# H616 register map
Vendor: Allwinner; Series: H616; File version: 0.1
CPU: other 0, little endian, MPU, no FPU, 0 interrupt priority bits
Registers are 32-bit, read-write, reset 0x0 unless marked. A register's access mark holds for its fields unless they carry their own. Offsets are from the block's base; [hi:lo] are bit positions; {n}, {i} and the like mark numbered series; 'fields as' and 'values as' point back to an identical list.

## NDFC
Base 0x04011000
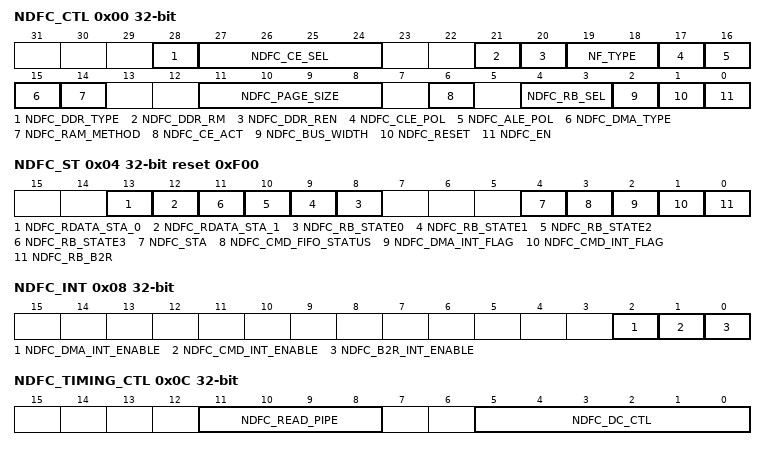
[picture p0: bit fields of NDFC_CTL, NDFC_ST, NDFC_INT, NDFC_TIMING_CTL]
0x00 NDFC_CTL — NDFC Configure and Control Register
  [28] NDFC_DDR_TYPE — Type of DDR data interface This bit is valid when NF_TYPE is 0x2 or 0x3. 0: DDR 1: DDR2
    0=DDR; 1=DDR2
  [27:24] NDFC_CE_SEL — Chip Select for NAND Flash Chips 0000: NDFC Select Chip 0 0001: NDFC Select Chip 1 0010: NDFC Select Chip 2 0011: NDFC Select Chip 3 0100: NDFC Select Chip 4 0101: NDFC Select Chip 5 0110: NDFC Select Chip 6 0111: NDFC Select Chip 7 1000: NDFC Select Chip 8 1001: NDFC Select Chip 9 1010: NDFC Select Chip 10 1011: NDFC Select Chip 11 1100: NDFC Select Chip 12 1101: NDFC Select Chip 13 1110: NDFC Select Chip 14 1111: NDFC Select Chip 15
    {v}=NDFC_Select_Chip_{v} (v=0..15)
  [21] NDFC_DDR_RM — DDR Repeat Data Mode 0: Lower byte 1: Higher byte
    0=Lower byte; 1=Higher byte
  [20] NDFC_DDR_REN — DDR Repeat Enable 0: Disable 1: Enable
    0=Disable; 1=Enable
  [19:18] NF_TYPE — NAND Flash Type 00: Normal SDR NAND 01: Reserved 10: ONFI DDR NAND 11: Toggle DDR NAND
    0=Normal SDR NAND; 2=ONFI (ONFI DDR NAND); 3=Toggle DDR NAND
  [17] NDFC_CLE_POL — NDFC Command Latch Enable (CLE) Signal Polarity Select 0: High active 1: Low active
    0=High active; 1=Low (Low active)
  [16] NDFC_ALE_POL — NDFC Address Latch Enable (ALE) Signal Polarity Select 0: High active 1: Low active
    0=High active; 1=Low (Low active)
  [15] NDFC_DMA_TYPE — 0: Dedicated DMA 1: Normal DMA
    0=Dedicated DMA; 1=Normal DMA
  [14] NDFC_RAM_METHOD — Access internal RAM method 0: Access internal RAM by AHB method 1: Access internal RAM by DMA method
    0=Access internal RAM by AHB method; 1=Access internal RAM by DMA method
  [11:8] NDFC_PAGE_SIZE — 000: 1KB 001: 2KB 010: 4KB 011: 8KB 100: 16KB 101: 32KB The page size is for main field data.
  [6] NDFC_CE_ACT — Chip Select Signal CE# Control during NAND Operation 0: De-active Chip Select Signal NDFC_CE# during data loading, serial access and other no operation stage for power consumption. NDFC automatic controls Chip Select Signals. 1: Chip select signal NDFC_CE# is always active after NDFC is enabled
    0=De-active Chip Select Signal NDFC_CE# during data loading, serial access and other no operation stage for power consumption. NDFC automatic controls Chip Select Signals.; 1=Chip select signal NDFC_CE# is always active after NDFC is enabled
  [4:3] NDFC_RB_SEL — NDFC External R/B Signal Select The value 0-3 selects the external R/B signal. The same R/B signal can be used for multiple chip select flash.
  [2] NDFC_BUS_WIDTH — 0: 8-bit bus 1: 16-bit bus
    0=8-bit bus; 1=16-bit bus
  [1] NDFC_RESET write-1-clears — NDFC Reset Write 1 to reset NDFC and clear to 0 after reset
  [0] NDFC_EN — NDFC Enable Control 0: Disable NDFC 1: Enable NDFC
    0=Disable NDFC; 1=Enable NDFC
0x04 NDFC_ST reset 0xF00 — NDFC Status Information Register
  [13] NDFC_RDATA_STA_0 ro — 0: The number of bit 1 during current read operation is more than threshold value. 1: The number of bit 1 during current read operation is less than or equal to threshold value. This field only is valid when NDFC_RDATA_STA_EN is 1. The threshold value is configured in NDFC_RDATA_STA_TH.
    0=more (The number of bit 1 during current read operation is more than threshold value.); 1=less (The number of bit 1 during current read operation is less than or equal to threshold value. This field only is valid when NDFC_RDATA_STA_EN is 1. The threshold value is configured in NDFC_RDATA_STA_TH.)
  [12] NDFC_RDATA_STA_1 ro — 0: The number of bit 0 during current read operation is more than threshold value. 1: The number of bit 0 during current read operation is less than or equal to the threshold value. This field only is valid when NDFC_RDATA_STA_EN is 1. The threshold value is configured in NDFC_RDATA_STA_TH.
    0=more (The number of bit 0 during current read operation is more than threshold value.); 1=less (The number of bit 0 during current read operation is less than or equal to the threshold value. This field only is valid when NDFC_RDATA_STA_EN is 1. The threshold value is configured in NDFC_RDATA_STA_TH.)
  [n+8] NDFC_RB_STATE{n} ro (n=0..3) — NAND Flash R/B {n} Line State 0: NAND Flash in BUSY State 1: NAND Flash in READY State
    0=NAND Flash in BUSY State; 1=NAND Flash in READY State
  [4] NDFC_STA ro — 0: NDFC FSM in IDLE state 1: NDFC FSM in BUSY state When NDFC_STA is 0, NDFC can accept new command and process command.
    0=NDFC FSM in IDLE state; 1=NDFC FSM in BUSY state When NDFC_STA is 0, NDFC can accept new command and process command
  [3] NDFC_CMD_FIFO_STATUS ro — 0: Command FIFO not full and can receive new command 1: Full and waiting NDFC to process commands in FIFO Since there is only one 32-bit FIFO for command. When NDFC latches one command, command FIFO is free and can accept another new command.
    0=Command FIFO not full and can receive new command; 1=Full and waiting NDFC to process commands in FIFO Since there is only one 32-bit FIFO for command. When NDFC latches one command, command FIFO is free and can accept another new command.
  [2] NDFC_DMA_INT_FLAG write-1-clears — When it is 1, it means that a pending DMA is completed. It will be cleared after writing 1 to this bit or it will be automatically cleared before FSM processing an new command.
  [1] NDFC_CMD_INT_FLAG write-1-clears — When it is 1, it means that NDFC has finished one Normal Command Mode or one Batch Command Work Mode. It will be cleared after writing 1 to this bit or it will be automatically cleared before FSM processing an new command.
  [0] NDFC_RB_B2R write-1-clears — When it is 1, it means that NDFC_R/B# signal is transferred from BUSY state to READY state. It will be cleared after writing 1 to this bit.
0x08 NDFC_INT — NDFC Interrupt Control Register
  [2] NDFC_DMA_INT_ENABLE — Enable or disable interrupt when a pending DMA is completed.
  [1] NDFC_CMD_INT_ENABLE — Enable or disable interrupt when NDFC has finished the procession of a single command in normal command work mode or one batch command work mode. 0: Disable 1: Enable
    0=Disable; 1=Enable
  [0] NDFC_B2R_INT_ENABLE — Enable or disable interrupt when NDFC_RB# signal is transferring from BUSY state to READY state. 0: Disable 1: Enable
    0=Disable; 1=Enable
0x0C NDFC_TIMING_CTL — NDFC Timing Control Register
  [11:8] NDFC_READ_PIPE — In SDR mode: 00: Normal 01: EDO 10: E-EDO Others: Reserved In DDR mode: 1~15 is valid.(These bits configure the number of clock when data is valid after RE#`s falling edge)
  [5:0] NDFC_DC_CTL — NDFC Delay Chain Control. These bits are only valid in DDR data interface, and configure the relative phase between DQS and DQ[0...7] .
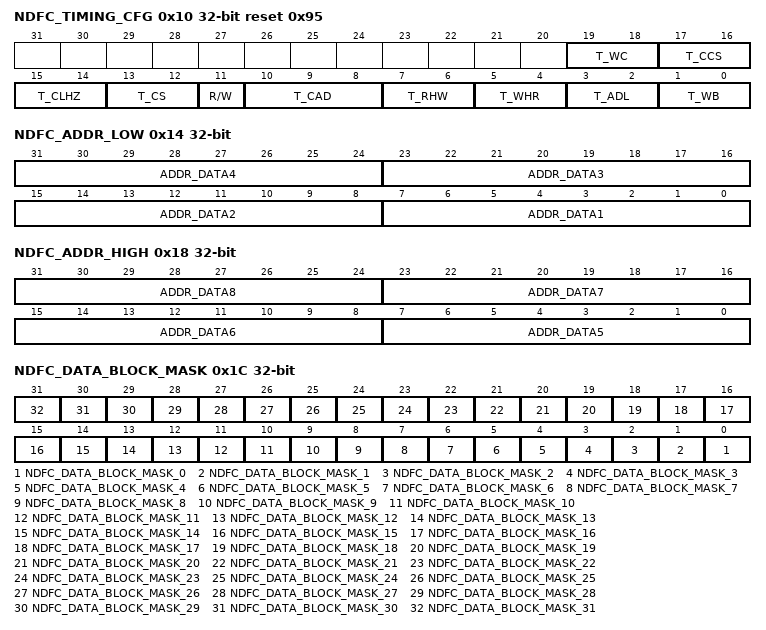
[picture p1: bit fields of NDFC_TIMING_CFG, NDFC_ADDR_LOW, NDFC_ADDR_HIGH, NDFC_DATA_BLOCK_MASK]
0x10 NDFC_TIMING_CFG reset 0x95 — NDFC Timing Configure Register
  [19:18] T_WC — Write Cycle Time 00: 1*2T 01: 2*2T 10: 3*2T 11: 4*2T
    {v}=_{v+1}_times_2T ({v+1}*2T) (v=0..3)
  [17:16] T_CCS — Change Column Setup Time 00: 12*2T 01: 20*2T 10: 28*2T 11: 60*2T
    0=_12_times_2T (12*2T); 1=_20_times_2T (20*2T); 2=_28_times_2T (28*2T); 3=_60_times_2T (60*2T)
  [15:14] T_CLHZ — CLE High to Output Hi-z 00: 2*2T 01: 8*2T 10: 16*2T 11: 31*2T
    0=_2_times_2T (2*2T); 1=_8_times_2T (8*2T); 2=_16_times_2T (16*2T); 3=_31_times_2T (31*2T)
  [13:12] T_CS — CE Setup Time 00: 2*2T 01: 8*2T 10: 16*2T 11: 31*2T
    values as T_CLHZ
  [11] R/W — 0x0 T_CDQSS DQS Setup Time for Data Input Start 0: 4*2T 1: 20*2T
    0=_4_times_2T (4*2T); 1=_20_times_2T (20*2T)
  [10:8] T_CAD — Command, Address, Data Delay 000: 2*2T 001: 6*2T 010: 10*2T 011: 14*2T 100: 22*2T 101: 30*2T 110/111: 62*2T
    0=_2_times_2T (2*2T); 1=_6_times_2T (6*2T); 2=_10_times_2T (10*2T); 3=_14_times_2T (14*2T); 4=_22_times_2T (22*2T); 5=_30_times_2T (30*2T 110/111: 62*2T)
  [7:6] T_RHW — Cycle Number from RE# High to WE# Low 00: 4*2T 01: 12*2T 10: 20*2T 11: 28*2T
    0=_4_times_2T (4*2T); 1=_12_times_2T (12*2T); 2=_20_times_2T (20*2T); 3=_28_times_2T (28*2T)
  [5:4] T_WHR — Cycle Number from WE# High to RE# Low 00: 0*2T 01: 6*2T 10: 14*2T 11: 22*2T
    0=_0_times_2T (0*2T); 1=_6_times_2T (6*2T); 2=_14_times_2T (14*2T); 3=_22_times_2T (22*2T)
  [3:2] T_ADL — Cycle Number from Address to Data Loading 00: 0*2T 01: 6*2T 10: 14*2T 11: 22*2T
    values as T_WHR
  [1:0] T_WB — Cycle Number from WE# High to Busy 00:14*2T 01: 22*2T 10: 30*2T 11: 38*2T
    1=_22_times_2T (22*2T); 2=_30_times_2T (30*2T); 3=_38_times_2T (38*2T)
0x14 NDFC_ADDR_LOW — NDFC Low Word Address Register
  [31:24] ADDR_DATA4 — NAND Flash 4th Cycle Address Data
  [23:16] ADDR_DATA3 — NAND Flash 3rd Cycle Address Data
  [15:8] ADDR_DATA2 — NAND Flash 2nd Cycle Address Data
  [7:0] ADDR_DATA1 — NAND Flash 1st Cycle Address Data
0x18 NDFC_ADDR_HIGH — NDFC High Word Address Register
  [8n-33:8n-40] ADDR_DATA{n} (n=5..8) — NAND Flash {n}th Cycle Address Data
0x1C NDFC_DATA_BLOCK_MASK
  [all] fields
    0=Disable; 1=Enable 1 data block = 1024 bytes main field data
  [n] NDFC_DATA_BLOCK_MASK_{n} (n=0..31) — It is used to indicate the data block {n} should be written or read during batch command procession(NDFC_CMD_TYPE=0x10 in NDFC_CMD ). 0: Disable 1: Enable 1 data block = 1024 bytes main field data.
0x20 NDFC_CNT — NDFC Data Counter Register
  [9:0] NDFC_DATA_CNT — Transfer Data Byte Counter The length can be set from 1 byte to 1024 bytes. However, 1024 bytes is set when it is zero.
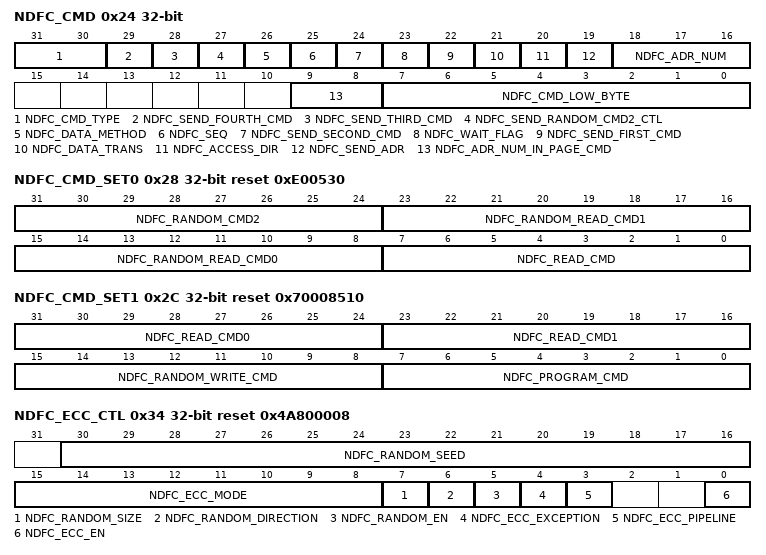
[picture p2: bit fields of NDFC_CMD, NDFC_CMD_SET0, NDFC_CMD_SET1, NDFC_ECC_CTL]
0x24 NDFC_CMD — NDFC Commands IO Register
  [31:30] NDFC_CMD_TYPE — 00: Common command for normal operation 01: Special command for Flash spare field operation 10: Page command for batch process operation 11: Reserved
    0=Common command for normal operation; 1=Special command for Flash spare field operation; 2=Page command for batch process operation
  [29] NDFC_SEND_FOURTH_CMD — 0: Donot send fourth set command 1: Send it on the external memory`s bus It is used for EF-NAND page read.
    0=Donot send fourth set command; 1=Send it on the external memory`s bus It is used for EF-NAND page read
  [28] NDFC_SEND_THIRD_CMD — 0: Donot send third set command 1: Send it on the external memory`s bus It is used for EF-NAND page read.
    0=Donot send third set command; 1=Send it on the external memory`s bus It is used for EF-NAND page read
  [27] NDFC_SEND_RANDOM_CMD2_CTL — 0: Donot send random cmd2 (NDFC_RANDOM_CMD2) 1: Send random cmd2
    0=Donot send random cmd2 (NDFC_RANDOM_CMD2); 1=Send random cmd2
  [26] NDFC_DATA_METHOD — Data swap method when the internal RAM and system memory It is only active for common command and special command. 0: No action 1: DMA transfer automatically It only is active when NDFC_RAM_METHOD is 1. If this bit is set to 1, NDFC should setup DRQ to fetch data before output to Flash or NDFC should setup DRQ to send to system memory after fetching data from Flash. If this bit is set to 0, NDFC output the data in internal RAM or do nothing after fetching data from Flash.
    0=No_action; 1=DMA (DMA transfer automatically It only is active when NDFC_RAM_METHOD is 1. If this bit is set to 1, NDFC should setup DRQ to fetch data before output to Flash or NDFC should setup DRQ to send to system memory after fetching data from Flash. If this bit is set to 0, NDFC output the data in internal RAM or do nothing after fetching data from Flash.)
  [25] NDFC_SEQ — User data & BCH check word position. It only is active for Page Command, donot care about this bit for other two commands. 0: Interleave Method (on page spare area) 1: Sequence Method (following data block)
    0=Interleave Method (on page spare area); 1=Sequence Method (following data block)
  [24] NDFC_SEND_SECOND_CMD — 0: Donot send second set command 1: Send it on the external memory`s bus
    0=Donot send second set command; 1=Send it on the external memory`s bus
  [23] NDFC_WAIT_FLAG — 0: NDFC can transfer data regardless of the internal NDFC_RB wire 1: NDFC can transfer data when the internal NDFC_RB wire is READY; otherwise it cannot when the internal NDFC_RB wire is BUSY
    0=NDFC can transfer data regardless of the internal NDFC_RB wire; 1=NDFC can transfer data when the internal NDFC_RB wire is READY; otherwise it cannot when the internal NDFC_RB wire is BUSY
  [22] NDFC_SEND_FIRST_CMD — 0: Donot send first set command 1: Send it on the external memory`s bus
    0=Donot send first set command; 1=Send it on the external memory`s bus
  [21] NDFC_DATA_TRANS — 0: No data transfer on external memory bus 1: Data transfer and direction is decided by the field NDFC_ACCESS_DIR
    0=No data transfer on external memory bus; 1=Data transfer and direction is decided by the field NDFC_ACCESS_DIR
  [20] NDFC_ACCESS_DIR — 0: Read NAND Flash 1: Write NAND Flash
    0=Read NAND Flash; 1=Write NAND Flash
  [19] NDFC_SEND_ADR — 0: Donot send ADDRESS 1: Send N cycles ADDRESS, the number N is specified by NDFC_ADR_NUM field
    0=Donot send ADDRESS; 1=Send N cycles ADDRESS, the number N is specified by NDFC_ADR_NUM field
  [18:16] NDFC_ADR_NUM — Address Cycles` Number 000: 1 cycle address field 001: 2 cycles address field 010: 3 cycles address field 011: 4 cycles address field 100: 5 cycles address field 101: 6 cycles address field 110: 7 cycles address field 111: 8 cycles address field
    0=1 cycle address field; {v}={v+1} cycles address field (v=1..7)
  [9:8] NDFC_ADR_NUM_IN_PAGE_CMD — The number of address cycles during page command. 00: 2 address cycles 11: 5 address cycles Others: reserved
    0=2 address cycles; 3=5 address cycles Others: reserved
  [7:0] NDFC_CMD_LOW_BYTE — NDFC command low byte data This command will be sent to external Flash by NDFC.
0x28 NDFC_CMD_SET0 reset 0xE00530
  [31:24] NDFC_RANDOM_CMD2 — Used for Batch Operation
  [23:16] NDFC_RANDOM_READ_CMD1 — Used for Batch Read Operation
  [15:8] NDFC_RANDOM_READ_CMD0 — Used for Batch Read Operation
  [7:0] NDFC_READ_CMD — Used for Batch Read Operation
0x2C NDFC_CMD_SET1 reset 0x70008510
  [31:24] NDFC_READ_CMD0 — Used for EF-NAND Page Read Operation
  [23:16] NDFC_READ_CMD1 — Used for EF-NAND Page Read Operation
  [15:8] NDFC_RANDOM_WRITE_CMD — Used for Batch Write Operation
  [7:0] NDFC_PROGRAM_CMD — Used for Batch Write Operation
0x34 NDFC_ECC_CTL reset 0x4A800008 — NDFC ECC Control Register
  [30:16] NDFC_RANDOM_SEED — The seed value for randomize engine. It is only active when NDFC_RANDOM_EN is set to `1`.
  [15:8] NDFC_ECC_MODE — 00000000: BCH-16 00000001: BCH-24 00000010: BCH-28 00000011: BCH-32 00000100: BCH-40 00000101: BCH-44 00000110: BCH-48 00000111: BCH-52 00001000: BCH-56 00001001: BCH-60 00001010: BCH-64 00001011: BCH-68 00001100: BCH-72 00001101: BCH-76 00001110: BCH-80 Others : Reserved
    0=BCH_minus_16 (BCH-16); 1=BCH_minus_24 (BCH-24); 2=BCH_minus_28 (BCH-28); 3=BCH_minus_32 (BCH-32); 4=BCH_minus_40 (BCH-40); 5=BCH_minus_44 (BCH-44); 6=BCH_minus_48 (BCH-48); 7=BCH_minus_52 (BCH-52); 8=BCH_minus_56 (BCH-56); 9=BCH_minus_60 (BCH-60); 10=BCH_minus_64 (BCH-64); 11=BCH_minus_68 (BCH-68); 12=BCH_minus_72 (BCH-72); 13=BCH_minus_76 (BCH-76); 14=BCH_minus_80 (BCH-80 Others : Reserved)
  [7] NDFC_RANDOM_SIZE — 0: ECC block size 1: Page size
    0=ECC (ECC block size); 1=Page size
  [6] NDFC_RANDOM_DIRECTION — 0: LSB first 1: MSB first
    0=LSB (LSB first); 1=MSB (MSB first)
  [5] NDFC_RANDOM_EN — 0: Disable Data Randomize 1: Enable Data Randomize
    0=Disable Data Randomize; 1=Enable Data Randomize
  [4] NDFC_ECC_EXCEPTION — 0: Normal ECC 1: For ECC, there is an exception. If all data is 0xff or 0x00 for the block. When reading this page, ECC assumes that it is right. For this case, no error information is reported.
    0=Normal ECC; 1=For (For ECC, there is an exception. If all data is 0xff or 0x00 for the block. When reading this page, ECC assumes that it is right. For this case, no error information is reported.)
  [3] NDFC_ECC_PIPELINE — Pipeline function enable or disable for batch command 0: Error Correction function no pipeline with next block operation 1: Error Correction pipeline
    0=Error Correction function no pipeline with next block operation; 1=Error_Correction_pipeline
  [0] NDFC_ECC_EN — 0: ECC is OFF 1: ECC is ON
    0=OFF (ECC is OFF); 1=ON (ECC is ON)
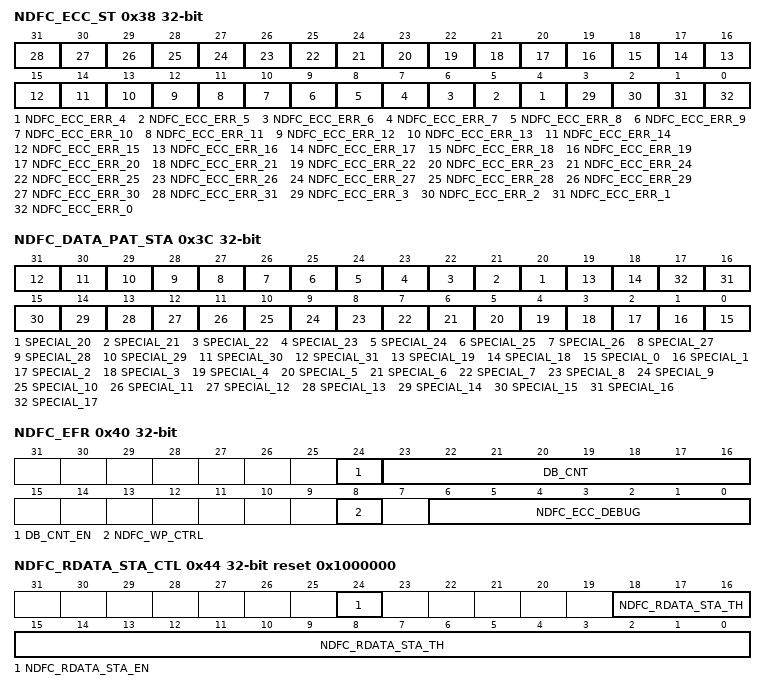
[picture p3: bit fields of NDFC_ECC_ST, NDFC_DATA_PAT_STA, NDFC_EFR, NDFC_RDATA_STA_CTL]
0x38 NDFC_ECC_ST — NDFC ECC Status Register
  [n] NDFC_ECC_ERR_{n} ro (n=4..31) — Error information bit of Data Block {n} 0: ECC can correct these error bits or there is no error bit 1: Error bits number beyond of ECC correction capability and cannot correct them The bit[{n}] of this register is corresponding the {n}th ECC data block. 1 ECC Data Block = 1024 bytes.
    0=ECC (ECC can correct these error bits or there is no error bit); 1=Error bits number beyond of ECC correction capability and cannot correct them The bit[{n}] of this register is corresponding the {n}th ECC data block. 1 ECC Data Block = 1024 bytes.
  [3] NDFC_ECC_ERR_3 ro — Error information bit of Data Block 3 0: ECC can correct these error bits or there is no error bit 1: Error bits number beyond of ECC correction capability and cannot correct them The bit[3] of this register is corresponding the 3rd ECC data block. 1 ECC Data Block = 1024 bytes.
    0=ECC (ECC can correct these error bits or there is no error bit); 1=Error bits number beyond of ECC correction capability and cannot correct them The bit[3] of this register is corresponding the 3rd ECC data block. 1 ECC Data Block = 1024 bytes.
  [2] NDFC_ECC_ERR_2 ro — Error information bit of Data Block 2 0: ECC can correct these error bits or there is no error bit 1: Error bits number beyond of ECC correction capability and cannot correct them The bit[2] of this register is corresponding the 2nd ECC data block. 1 ECC Data Block = 1024 bytes.
    0=ECC (ECC can correct these error bits or there is no error bit); 1=Error bits number beyond of ECC correction capability and cannot correct them The bit[2] of this register is corresponding the 2nd ECC data block. 1 ECC Data Block = 1024 bytes.
  [1] NDFC_ECC_ERR_1 ro — Error information bit of Data Block 1 0: ECC can correct these error bits or there is no error bit 1: Error bits number beyond of ECC correction capability and cannot correct them The bit[1] of this register is corresponding the 1st ECC data block. 1 ECC Data Block = 1024 bytes.
    0=ECC (ECC can correct these error bits or there is no error bit); 1=Error bits number beyond of ECC correction capability and cannot correct them The bit[1] of this register is corresponding the 1st ECC data block. 1 ECC Data Block = 1024 bytes.
  [0] NDFC_ECC_ERR_0 ro — Error information bit of Data Block 0 0: ECC can correct these error bits or there is no error bit 1: Error bits number beyond of ECC correction capability and cannot correct them The bit[0] of this register is corresponding the 0 ECC data block. 1 ECC Data Block = 1024 bytes.
    0=ECC (ECC can correct these error bits or there is no error bit); 1=Error bits number beyond of ECC correction capability and cannot correct them The bit[0] of this register is corresponding the 0 ECC data block. 1 ECC Data Block = 1024 bytes.
0x3C NDFC_DATA_PAT_STA — NDFC Data Pattern Status Register
  [all] fields
    0=No_found; 1=Special pattern is found The register of NDFC_PAT_ID would indicate which kind of pattern is found
  [n] SPECIAL_{n} ro (n=20..31) — Special pattern (all 0x00 or all 0xff) found flag for Data Block {n} when read from external NAND flash. 0: No found 1: Special pattern is found The register of NDFC_PAT_ID would indicate which kind of pattern is found.
  [19] SPECIAL_19 ro — Special pattern (all 0x00 or all 0xff) found Flag for Data Block 19 when read from external NAND flash. 0: No found 1: Special pattern is found The register of NDFC_PAT_ID would indicate which kind of pattern is found.
  [18] SPECIAL_18 ro — Special pattern (all 0x00 or all 0xff) Found flag for Data Block 18 when read from external NAND flash. 0: No found 1: Special pattern is found The register of NDFC_PAT_ID would indicate which kind of pattern is found.
  [n] SPECIAL_{n} ro (n=0..17) — Special pattern (all 0x00 or all 0xff) found flag for Data Block {n} when read from external NAND flash. 0: No found 1: Special pattern is found The register of NDFC_PAT_ID would indicate which kind of pattern is found.
0x40 NDFC_EFR — NDFC Enhanced Feature Register
  [24] DB_CNT_EN — Dummy_Byte_Count_EN 0:Disable fill dummy byte 1:Enable fill dummy byte
  [23:16] DB_CNT — Dummy_Byte_Count After PAGE CMD operation finishing sending out the main data , user data and ECC code, controller would send dummy byte to fill the unused space in one page. It is only valid in PAGE CMD operation(NDFC_CMD_TYPE=0x3), and this
  [8] NDFC_WP_CTRL — NAND Flash Write Protect Control Bit 0: Write Protect is active 1: Write Protect is not active When this bit is `0`, WP signal line is low level and external NAND flash is on protected state.
    0=active (Write Protect is active); 1=not_active (Write Protect is not active When this bit is `0`, WP signal line is low level and external NAND flash is on protected state.)
  [6:0] NDFC_ECC_DEBUG — For the purpose of debugging ECC engine, special error bits are inserted before writing external Flash Memory. 0: No error is inserted (ECC Normal Operation) n: N bits error are inserted
0x44 NDFC_RDATA_STA_CTL reset 0x1000000 — NDFC Read Data Status Control Register
  [24] NDFC_RDATA_STA_EN — 0: Disable to count the number of bit 1 and bit 0 during current read operation 1: Enable to count the number of bit 1 and bit 0 during current read operation The number of bit 1 and bit 0 during current read operation can be used to check whether a page is blank or bad.
    0=Disable to count the number of bit 1 and bit 0 during current read operation; 1=Enable to count the number of bit 1 and bit 0 during current read operation The number of bit 1 and bit 0 during current read operation can be used to check whether a page is blank or bad
  [18:0] NDFC_RDATA_STA_TH — The threshold value to generate data status If the number of bit 1 during current read operation is less than or equal to threshold value, the bit 13 of NDFC_ST register will be set. If the number of bit 0 during current read operation is less than or equal to threshold value, the bit 12 of NDFC_ST register will be set.
0x48 NDFC_RDATA_STA_0 — NDFC Read Data Status Register 0
  [31:0] BIT_CNT_1 ro — The number of input bit 1 during current command. It will be cleared automatically when next command is executed.
0x4C NDFC_RDATA_STA_1 — NDFC Read Data Status Register 1
  [31:0] BIT_CNT_0 ro — The number of input bit 0 during current command. It will be cleared automatically when next command is executed.
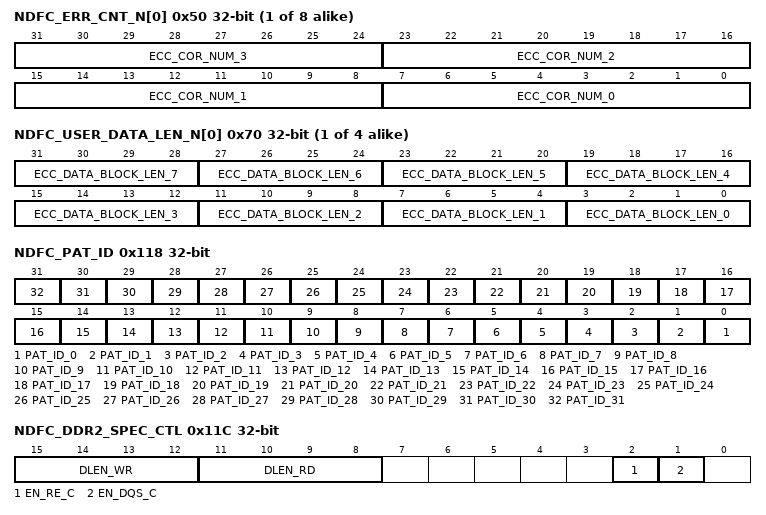
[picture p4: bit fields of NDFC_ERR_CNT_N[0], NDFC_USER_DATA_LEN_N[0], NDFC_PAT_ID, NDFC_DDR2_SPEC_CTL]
{0x50+4i} NDFC_ERR_CNT_N[{i}] (i=0..7) — NDFC Error Counter Register(N from 0 to 7)
  [8n+7:8n] ECC_COR_NUM_{n} ro (n=0..3) — ECC Corrected Bits Number for ECC Data Block[N*0x04+M] 00000000: No corrected bits 00000001: 1 corrected bit 00000010: 2 corrected bits ..... 01010000 : 80 corrected bits Others: Reserved
{0x70+4i} NDFC_USER_DATA_LEN_N[{i}] (i=0..3) — NDFC User Data Length Register(N from 0 to 3)
  [4n+3:4n] ECC_DATA_BLOCK_LEN_{n} (n=0..7) — It's used to indicate user data's length of ECC DATA BLOCK[0x08*N+M]. 0000 : no user data 0001 : 4 bytes user data 0010 : 8 bytes user data 0011 : 12 bytes user data 0100 : 16 bytes user data 0101 : 20 bytes user data 0110 : 24 bytes user data 0111 : 28 bytes user data 1000 : 32 bytes user data Other : reserved
{0x80+4i} NDFC_USER_DATA_N[{i}] (i=0..31) reset 0xFFFFFFFF — NDFC User Data Field Register N (N from 0 to 31)
  [31:0] USER_DATA — All of the user data in one page is stored in NDFC_USER_DATA_N. The start register address of each ECC DATA BLOCK's user data is determined by its length configured in NDFC_USER_DATA_LEN_N. For example: ECC DATA BLOCK[0] user data len = 8 bytes, address = 0x80 ECC DATA BLOCK[1] user data len = 0 byte, ECC DATA BLOCK[2] user data len = 4 bytes, address = 0x80+8 ECC DATA BLOCK[3] user data len = 4 bytes, address = 0x80+8+4 ECC DATA BLOCK[4] user data len = 0 byte ECC DATA BLOCK[5] user data len = 16 bytes, address = 0x80+8+4+4 ECC DATA BLOCK[6] user data len = 0 byte ECC DATA BLOCK[7] user data len = 0 byte
0x110 NDFC_EFNAND_STATUS
  [7:0] EF_NAND_STATUS ro — The status value for EF-NAND page read operation
0x114 NDFC_SPARE_AREA reset 0x400
  [15:0] NDFC_SPARE_ADR — This value indicates the spare area first byte address for NDFC interleave page operation.
0x118 NDFC_PAT_ID — NDFC Pattern ID Register
  [n] PAT_ID_{n} ro (n=0..31) — Special Pattern ID for ECC data block[n] 0: All 0x00 is found 1: All 0xFF is found
0x11C NDFC_DDR2_SPEC_CTL — NDFC DDR2 Specific Control Register
  [15:12] DLEN_WR — The number of latency DQS cycle for write 0000: No latency 0001: One latency DQS cycle 0010: Two latency DQS cycle 0011: Four latency DQS cycle
    0=No_latency; 1=One (One latency DQS cycle); 2=Two (Two latency DQS cycle); 3=Four latency DQS cycle
  [11:8] DLEN_RD — The number of latency DQS cycle for read 0000: No latency 0001: One latency DQS cycle 0010: Two latency DQS cycle 0011: Four latency DQS cycle
    values as DLEN_WR
  [2] EN_RE_C — Enable the complementary RE# signal 0: Disable 1: Enable
    0=Disable; 1=Enable
  [1] EN_DQS_C — Enable the complementary DQS signal 0: Disable 1: Enable
    0=Disable; 1=Enable
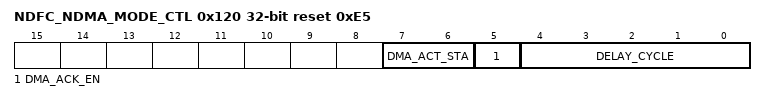
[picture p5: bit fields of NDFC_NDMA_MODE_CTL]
0x120 NDFC_NDMA_MODE_CTL reset 0xE5 — NDFC Normal DMA Mode Control Register
  [7:6] DMA_ACT_STA — 00:dma_active is low 01:dma_active is high 10:dma_active is controlled by dma_request(DRQ) 11:dma_active is controlled by controller
  [5] DMA_ACK_EN — 0: active fall do not care ack 1: active fall must after detect ack is high
    0=active fall do not care ack; 1=active fall must after detect ack is high
  [4:0] DELAY_CYCLE — The counts of hold cycles from DMA last signal high to dma_active high
0x200 NDFC_MDMA_DLBA_REG — NDFC MBUS DMA Descriptor List Base Address Register
  [31:0] NFC_MDMA_DESC_BASE_ADDR — Start Address of Descriptor List Contains the base address of the First Descriptor. The LSB bits [1:0] are ignored and taken as all-zero by the DMA internally. Hence these LSB bits are read-only.
0x204 NDFC_MDMA_STA — NDFC MBUS DMA Interrupt Status Register
  [31:0] NFC_MDMA_TRANS_FINISH_INT — Transfer Finish Interrupt Indicates that data transmission is finished for a descriptor. Writing a `1` clears this bit. Bit 0: Corresponding DMA descriptor 0 Bit 1: Corresponding DMA descriptor 1 ... Bit 31: Corresponding DMA descriptor 31
0x208 NDFC_DMA_INT_MASK — NDFC MBUS DMA Interrupt Enable Register
  [31:0] NFC_MDMA_TRANS_INT_ENB — Transfer Interrupt Enable When set, Transmit Interrupt is enabled. When reset, Transmit Interrupt is disabled. Bit 0: Corresponding DMA descriptor 0 Bit 1: Corresponding DMA descriptor 1 ... Bit 31: Corresponding DMA descriptor 31
0x20C NDFC_MDMA_CUR_DESC_ADDR — NDFC MBUS DMA Current Descriptor Address Register
  [31:0] CUR_DESC_ADDR ro — Current Descriptor Address Pointer Cleared on reset. Pointer updated by DMA during operation. This register points to the start address of the current descriptor read by the DMA.
0x210 NDFC_MDMA_CUR_BUF_ADDR — NDFC MBUS DMA Current Buffer Address Register
  [31:0] CUR_BUFF_ADDR ro — Current Buffer Address Pointer Cleared on Reset. Pointer updated by DMA during operation. This register points to the current Data Buffer Address being accessed by the DMA.
0x214 NDFC_DMA_CNT — NDFC DMA Byte Counter Register
  [15:0] DMA_CNT — DMA data counter, including MBUS DMA and Normal DMA
0x300 NDFC_IO_DATA — NDFC Input/Output Data Register
  [31:0] NDFC_IO_DATA — Read/Write data into internal RAM Access unit is 32-bit.
